# ATtiny10 device description
Architecture: AVR8L; Family: tinyAVR
Registers are 8-bit, access not given, no defined reset value unless marked. A register's access mark holds for its fields unless they carry their own. Offsets are from the block's base; [hi:lo] are bit positions.

## AC — Analog Comparator
Instances: AC 0x00
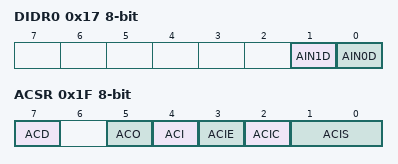
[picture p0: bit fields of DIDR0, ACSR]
0x17 DIDR0
  [1] AIN1D — AIN1 Digital Input Disable
  [0] AIN0D — AIN0 Digital Input Disable
0x1F ACSR — Analog Comparator Control And Status Register
  [7] ACD — Analog Comparator Disable
  [5] ACO — Analog Compare Output
  [4] ACI — Analog Comparator Interrupt Flag
  [3] ACIE — Analog Comparator Interrupt Enable
  [2] ACIC — Analog Comparator Input Capture Enable
  [1:0] ACIS — Analog Comparator Interrupt Mode Select bits
    0=INTERRUPT_ON_TOGGLE; 2=INTERRUPT_ON_FALLING_EDGE; 3=INTERRUPT_ON_RISING_EDGE

## CPU — CPU Registers
Instances: CPU 0x00
0x32 NVMCSR — Non-Volatile Memory Control and Status Register
  [7] NVMBSY — Non-Volatile Memory Busy
0x33 NVMCMD bits used 5:0 — Non-Volatile Memory Command
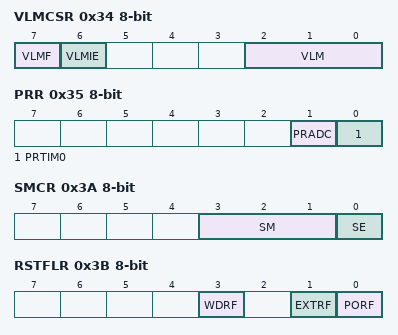
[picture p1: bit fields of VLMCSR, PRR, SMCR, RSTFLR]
0x34 VLMCSR — Vcc Level Monitoring Control and Status Register
  [7] VLMF — VLM Flag
  [6] VLMIE — VLM Interrupt Enable
  [2:0] VLM — Trigger Level of Voltage Level Monitor bits
0x35 PRR — Power Reduction Register
  [1] PRADC — Power Reduction ADC
  [0] PRTIM0 — Power Reduction Timer/Counter0
0x36 CLKPSR — Clock Prescale Register
  [3:0] CLKPS — Clock Prescaler Select Bits
    0=1; 1=2; 2=4; 3=8; 4=16; 5=32; 6=64; 7=128; 8=256
0x37 CLKMSR — Clock Main Settings Register
  [1:0] CLKMS — Clock Main Select Bits
0x39 OSCCAL — Oscillator Calibration Value
0x3A SMCR — Sleep Mode Control Register
  [3:1] SM — Sleep Mode Select Bits
    0=IDLE; 1=ADC (ADC Noise Reduction); 2=PDOWN (Power Down); 4=STDBY (Standby)
  [0] SE — Sleep Enable
0x3B RSTFLR — Reset Flag Register
  [3] WDRF — Watchdog Reset Flag
  [1] EXTRF — External Reset Flag
  [0] PORF — Power-on Reset Flag
0x3C CCP — Configuration Change Protection
0x3D SP 16-bit — Stack Pointer
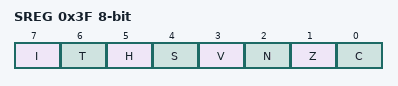
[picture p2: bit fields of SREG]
0x3F SREG — Status Register
  [7] I — Global Interrupt Enable
  [6] T — Bit Copy Storage
  [5] H — Half Carry Flag
  [4] S — Sign Bit
  [3] V — Two's Complement Overflow Flag
  [2] N — Negative Flag
  [1] Z — Zero Flag
  [0] C — Carry Flag

## PORTB — I/O Port
Instances: PORTB 0x00
0x00 PINB bits used 3:0 — Port B Data register
0x01 DDRB bits used 3:0 — Data Direction Register, Port B
0x02 PORTB bits used 3:0 — Input Pins, Port B
0x03 PUEB bits used 3:0 — Pull-up Enable Control Register
0x0C PORTCR — Port Control Register
  [1] BBMB — Break-Before-Make Mode Enable

## EXINT — External Interrupts
Instances: EXINT 0x00
0x10 PCMSK — Pin Change Mask Register
  [3:0] PCINT — Pin Change Enable Masks
0x11 PCIFR — Pin Change Interrupt Flag Register
  [0] PCIF0 — Pin Change Interrupt Flag 0
0x12 PCICR — Pin Change Interrupt Control Register
  [0] PCIE0 — Pin Change Interrupt Enable 0
0x13 EIMSK — External Interrupt Mask register
  [0] INT0 — External Interrupt Request 0 Enable
0x14 EIFR — External Interrupt Flag register
  [0] INTF0 — External Interrupt Flag 0
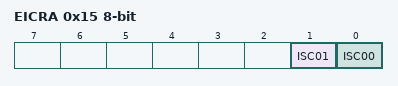
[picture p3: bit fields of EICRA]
0x15 EICRA — External Interrupt Control Register A
  [1] ISC01 — Interrupt Sense Control 0 Bit 1
  [0] ISC00 — Interrupt Sense Control 0 Bit 0

## TC0 (TC16 module) — Timer/Counter, 16-bit
Instances: TC0 0x00
0x22 ICR0 16-bit — Input Capture Register Bytes
0x24 OCR0B 16-bit — Timer/Counter0 Output Compare Register B
0x26 OCR0A 16-bit — Timer/Counter 0 Output Compare Register A
0x28 TCNT0 16-bit — Timer/Counter0
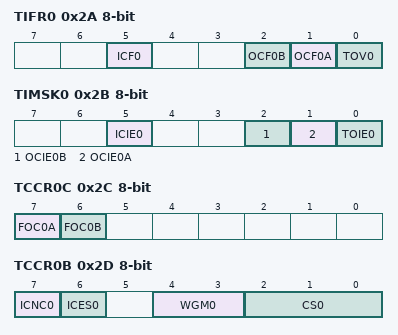
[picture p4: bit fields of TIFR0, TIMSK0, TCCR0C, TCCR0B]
0x2A TIFR0 — Overflow Interrupt Enable
  [5] ICF0 — Input Capture Flag
  [2] OCF0B — Timer Output Compare Flag 0B
  [1] OCF0A — Timer Output Compare Flag 0A
  [0] TOV0 — Timer Overflow Flag
0x2B TIMSK0 — Timer Interrupt Mask Register 0
  [5] ICIE0 — Input Capture Interrupt Enable
  [2] OCIE0B — Output Compare B Match Interrupt Enable
  [1] OCIE0A — Output Compare A Match Interrupt Enable
  [0] TOIE0 — Overflow Interrupt Enable
0x2C TCCR0C — Timer/Counter 0 Control Register C
  [7] FOC0A — Force Output Compare for Channel A
  [6] FOC0B — Force Output Compare for Channel B
0x2D TCCR0B — Timer/Counter 0 Control Register B
  [7] ICNC0 — Input Capture Noise Canceler
  [6] ICES0 — Input Capture Edge Select
  [4:3] WGM0 (bit 2 of the value upward) — Waveform Generation Mode
  [2:0] CS0 — Clock Select
    0=NO_CLOCK_SOURCE_STOPPED; 1=RUNNING_NO_PRESCALING; 2=RUNNING_CLK_8; 3=RUNNING_CLK_64; 4=RUNNING_CLK_256; 5=RUNNING_CLK_1024; 6=RUNNING_EXTCLK_TN_FALLING_EDGE; 7=RUNNING_EXTCLK_TN_RISING_EDGE
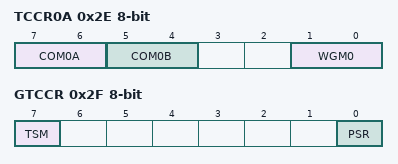
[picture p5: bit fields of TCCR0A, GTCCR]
0x2E TCCR0A — Timer/Counter 0 Control Register A
  [7:6] COM0A — Compare Output Mode for Channel A bits
  [5:4] COM0B — Compare Output Mode for Channel B bits
  [1:0] WGM0 — Waveform Generation Mode
0x2F GTCCR — General Timer/Counter Control Register
  [7] TSM — Timer Synchronization Mode
  [0] PSR — Prescaler Reset

## WDT — Watchdog Timer
Instances: WDT 0x00
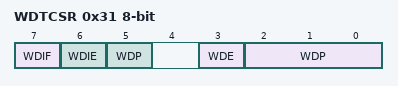
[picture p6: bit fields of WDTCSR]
0x31 WDTCSR — Watchdog Timer Control and Status Register
  [7] WDIF — Watchdog Timer Interrupt Flag
  [6] WDIE — Watchdog Timer Interrupt Enable
  [3] WDE — Watch Dog Enable
  [5,2:0] WDP — Watchdog Timer Prescaler Bits
    0=OSCILLATOR_CYCLES_2K; 1=OSCILLATOR_CYCLES_4K; 2=OSCILLATOR_CYCLES_8K; 3=OSCILLATOR_CYCLES_16K; 4=OSCILLATOR_CYCLES_32K; 5=OSCILLATOR_CYCLES_64K; 6=OSCILLATOR_CYCLES_128K; 7=OSCILLATOR_CYCLES_256K; 8=OSCILLATOR_CYCLES_512K; 9=OSCILLATOR_CYCLES_1024K
